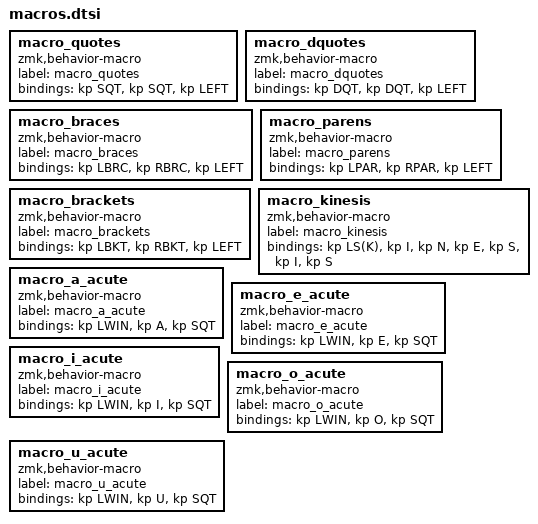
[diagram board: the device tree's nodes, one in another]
  macro_quotes: macro_quotes {
    compatible = "zmk,behavior-macro";
    label = "macro_quotes";
    #binding-cells = <0>;
    bindings = <&kp SQT>, <&kp SQT>, <&kp LEFT>;
  };
  macro_dquotes: macro_dquotes {
    compatible = "zmk,behavior-macro";
    label = "macro_dquotes";
    #binding-cells = <0>;
    bindings = <&kp DQT>, <&kp DQT>, <&kp LEFT>;
  };
  macro_braces: macro_braces {
    compatible = "zmk,behavior-macro";
    label = "macro_braces";
    #binding-cells = <0>;
    bindings = <&kp LBRC>, <&kp RBRC>, <&kp LEFT>;
  };
  macro_parens: macro_parens {
    compatible = "zmk,behavior-macro";
    label = "macro_parens";
    #binding-cells = <0>;
    bindings = <&kp LPAR>, <&kp RPAR>, <&kp LEFT>;
  };
  macro_brackets: macro_brackets {
    compatible = "zmk,behavior-macro";
    label = "macro_brackets";
    #binding-cells = <0>;
    bindings = <&kp LBKT>, <&kp RBKT>, <&kp LEFT>;
  };
  macro_kinesis: macro_kinesis {
    compatible = "zmk,behavior-macro";
    label = "macro_kinesis";
    #binding-cells = <0>;
    bindings = <&kp LS(K)>, <&kp I>, <&kp N>, <&kp E>, <&kp S>, <&kp I>, <&kp S>;
  };
  macro_a_acute: macro_a_acute {
    compatible = "zmk,behavior-macro";
    label = "macro_a_acute";
    #binding-cells = <0>;
    bindings = <&kp LWIN>, <&kp A>, <&kp SQT>; // Tasto Windows + A + SQT per "á"
  };
  macro_e_acute: macro_e_acute {
    compatible = "zmk,behavior-macro";
    label = "macro_e_acute";
    #binding-cells = <0>;
    bindings = <&kp LWIN>, <&kp E>, <&kp SQT>; // Tasto Windows + E + SQT per "é"
  };
  macro_i_acute: macro_i_acute {
    compatible = "zmk,behavior-macro";
    label = "macro_i_acute";
    #binding-cells = <0>;
    bindings = <&kp LWIN>, <&kp I>, <&kp SQT>; // Tasto Windows + I + SQT per "í"
  };
  macro_o_acute: macro_o_acute {
    compatible = "zmk,behavior-macro";
    label = "macro_o_acute";
    #binding-cells = <0>;
    bindings = <&kp LWIN>, <&kp O>, <&kp SQT>; // Tasto Windows + O + SQT per "ó"
  };
  macro_u_acute: macro_u_acute {
    compatible = "zmk,behavior-macro";
    label = "macro_u_acute";
    #binding-cells = <0>;
    bindings = <&kp LWIN>, <&kp U>, <&kp SQT>; // Tasto Windows + U + SQT per "ú"
  };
